# D2522AA register map
Vendor: Dialog; Series: D2522AA; File version: 1.2
CPU: CM0 r1p0, little endian, MPU, FPU, 3 interrupt priority bits
Registers are 32-bit, read-write, reset 0x0 unless marked. A register's access mark holds for its fields unless they carry their own. Offsets are from the block's base; [hi:lo] are bit positions; {n}, {i} and the like mark numbered series; 'fields as' and 'values as' point back to an identical list.

## RFCU_POWER — RFCU_POWER registers
Base 0x40020200
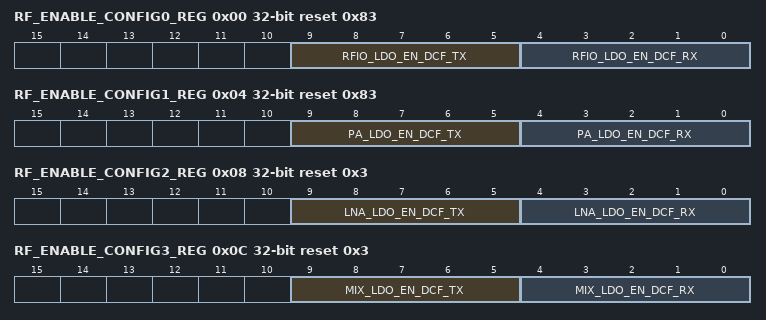
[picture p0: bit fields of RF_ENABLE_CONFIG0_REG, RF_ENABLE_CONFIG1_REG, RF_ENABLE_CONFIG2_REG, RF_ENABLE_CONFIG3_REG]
0x00 RF_ENABLE_CONFIG0_REG reset 0x83
  [9:5] RFIO_LDO_EN_DCF_TX — DCF timer for rfio_ldo_en in tx mode.
  [4:0] RFIO_LDO_EN_DCF_RX — DCF timer for rfio_ldo_en in rx mode
0x04 RF_ENABLE_CONFIG1_REG reset 0x83
  [9:5] PA_LDO_EN_DCF_TX — DCF timer for pa_ldo_en in tx mode
  [4:0] PA_LDO_EN_DCF_RX — DCF timer for pa_ldo_en in rx mode
0x08 RF_ENABLE_CONFIG2_REG reset 0x3
  [9:5] LNA_LDO_EN_DCF_TX — DCF timer for lna_ldo_en in tx mode
  [4:0] LNA_LDO_EN_DCF_RX — DCF timer for lna_ldo_en in rx mode
0x0C RF_ENABLE_CONFIG3_REG reset 0x3
  [9:5] MIX_LDO_EN_DCF_TX — DCF timer for mix_ldo_en in tx mode
  [4:0] MIX_LDO_EN_DCF_RX — DCF timer for mix_ldo_en in rx mode
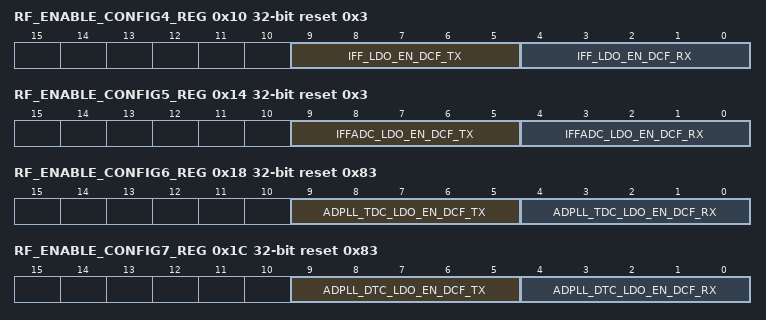
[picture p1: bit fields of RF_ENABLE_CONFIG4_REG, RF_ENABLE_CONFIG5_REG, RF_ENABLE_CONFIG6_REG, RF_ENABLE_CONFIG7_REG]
0x10 RF_ENABLE_CONFIG4_REG reset 0x3
  [9:5] IFF_LDO_EN_DCF_TX — DCF timer for iff_ldo_en in tx mode
  [4:0] IFF_LDO_EN_DCF_RX — DCF timer for iff_ldo_en in rx mode
0x14 RF_ENABLE_CONFIG5_REG reset 0x3
  [9:5] IFFADC_LDO_EN_DCF_TX — DCF timer for iffadc_ldo_en in tx mode
  [4:0] IFFADC_LDO_EN_DCF_RX — DCF timer for iffadc_ldo_en in rx mode
0x18 RF_ENABLE_CONFIG6_REG reset 0x83
  [9:5] ADPLL_TDC_LDO_EN_DCF_TX — DCF timer for adpll_tdc_ldo_en in tx mode
  [4:0] ADPLL_TDC_LDO_EN_DCF_RX — DCF timer for adpll_tdc_ldo_en in rx mode
0x1C RF_ENABLE_CONFIG7_REG reset 0x83
  [9:5] ADPLL_DTC_LDO_EN_DCF_TX — DCF timer for adpll_dtc_ldo_en in tx mode
  [4:0] ADPLL_DTC_LDO_EN_DCF_RX — DCF timer for adpll_dtc_ldo_en in rx mode
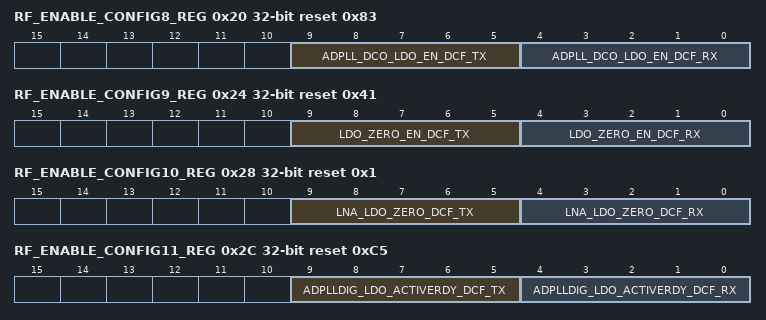
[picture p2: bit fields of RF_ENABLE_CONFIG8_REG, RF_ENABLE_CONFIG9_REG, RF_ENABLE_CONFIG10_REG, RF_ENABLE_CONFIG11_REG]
0x20 RF_ENABLE_CONFIG8_REG reset 0x83
  [9:5] ADPLL_DCO_LDO_EN_DCF_TX — DCF timer for adpll_dco_ldo_en in tx mode
  [4:0] ADPLL_DCO_LDO_EN_DCF_RX — DCF timer for adpll_dco_ldo_en in rx mode
0x24 RF_ENABLE_CONFIG9_REG reset 0x41
  [9:5] LDO_ZERO_EN_DCF_TX — DCF timer for ldo_zero_en in tx mode
  [4:0] LDO_ZERO_EN_DCF_RX — DCF timer for ldo_zero_en in rx mode
0x28 RF_ENABLE_CONFIG10_REG reset 0x1
  [9:5] LNA_LDO_ZERO_DCF_TX — DCF timer for lna_ldo_zero in tx mode
  [4:0] LNA_LDO_ZERO_DCF_RX — DCF timer for lna_ldo_zero in rx mode
0x2C RF_ENABLE_CONFIG11_REG reset 0xC5
  [9:5] ADPLLDIG_LDO_ACTIVERDY_DCF_TX — DCF timer for adplldig_ldo_activerdy in tx mode
  [4:0] ADPLLDIG_LDO_ACTIVERDY_DCF_RX — DCF timer for adplldig_ldo_activerdy in rx mode
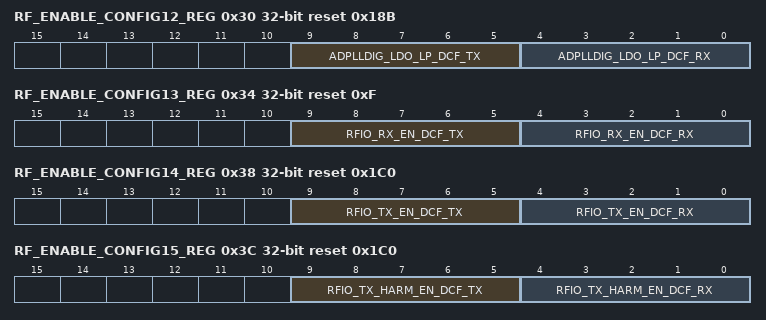
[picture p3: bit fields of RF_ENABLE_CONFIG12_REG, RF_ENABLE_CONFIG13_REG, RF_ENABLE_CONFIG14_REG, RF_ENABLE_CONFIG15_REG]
0x30 RF_ENABLE_CONFIG12_REG reset 0x18B
  [9:5] ADPLLDIG_LDO_LP_DCF_TX — DCF timer for adplldig_ldo_lp in tx mode
  [4:0] ADPLLDIG_LDO_LP_DCF_RX — DCF timer for adplldig_ldo_lp in rx mode
0x34 RF_ENABLE_CONFIG13_REG reset 0xF
  [9:5] RFIO_RX_EN_DCF_TX — DCF timer for rfio_rx_en in tx mode
  [4:0] RFIO_RX_EN_DCF_RX — DCF timer for rfio_rx_en in rx mode
0x38 RF_ENABLE_CONFIG14_REG reset 0x1C0
  [9:5] RFIO_TX_EN_DCF_TX — DCF timer for rfio_tx_en in tx mode
  [4:0] RFIO_TX_EN_DCF_RX — DCF timer for rfio_tx_en in rx mode
0x3C RF_ENABLE_CONFIG15_REG reset 0x1C0
  [9:5] RFIO_TX_HARM_EN_DCF_TX — DCF timer for rfio_tx_harm_en in tx mode
  [4:0] RFIO_TX_HARM_EN_DCF_RX — DCF timer for rfio_tx_harm_en in rx mode
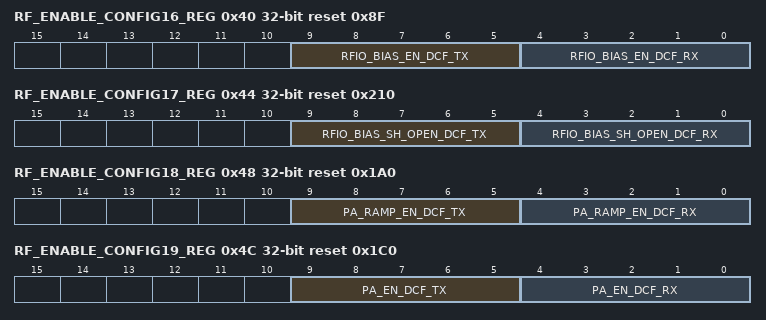
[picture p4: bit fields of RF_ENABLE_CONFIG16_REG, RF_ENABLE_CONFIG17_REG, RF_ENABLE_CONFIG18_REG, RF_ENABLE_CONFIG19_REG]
0x40 RF_ENABLE_CONFIG16_REG reset 0x8F
  [9:5] RFIO_BIAS_EN_DCF_TX — DCF timer for rfio_bias_en in tx mode
  [4:0] RFIO_BIAS_EN_DCF_RX — DCF timer for rfio_bias_en in rx mode
0x44 RF_ENABLE_CONFIG17_REG reset 0x210
  [9:5] RFIO_BIAS_SH_OPEN_DCF_TX — DCF timer for rfio_bias_sh_open in tx mode
  [4:0] RFIO_BIAS_SH_OPEN_DCF_RX — DCF timer for rfio_bias_sh_open in rx mode
0x48 RF_ENABLE_CONFIG18_REG reset 0x1A0
  [9:5] PA_RAMP_EN_DCF_TX — DCF timer for pa_ramp_en in tx mode
  [4:0] PA_RAMP_EN_DCF_RX — DCF timer for pa_ramp_en in rx mode
0x4C RF_ENABLE_CONFIG19_REG reset 0x1C0
  [9:5] PA_EN_DCF_TX — DCF timer for pa_en in tx mode
  [4:0] PA_EN_DCF_RX — DCF timer for pa_en in rx mode
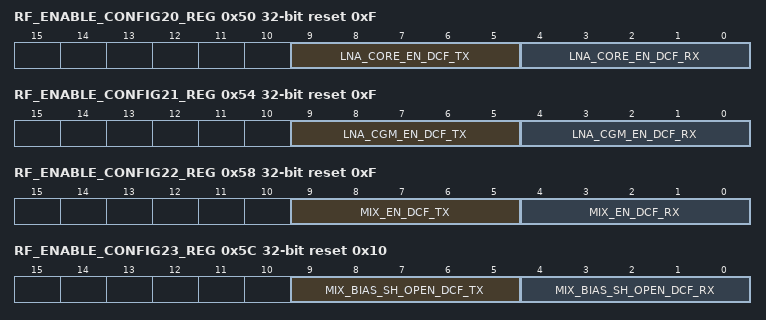
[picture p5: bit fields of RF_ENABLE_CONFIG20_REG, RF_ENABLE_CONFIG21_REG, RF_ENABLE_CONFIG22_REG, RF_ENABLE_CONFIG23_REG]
0x50 RF_ENABLE_CONFIG20_REG reset 0xF
  [9:5] LNA_CORE_EN_DCF_TX — DCF timer for lna_core_en in tx mode
  [4:0] LNA_CORE_EN_DCF_RX — DCF timer for lna_core_en in rx mode
0x54 RF_ENABLE_CONFIG21_REG reset 0xF
  [9:5] LNA_CGM_EN_DCF_TX — DCF timer for lna_cgm_en in tx mode
  [4:0] LNA_CGM_EN_DCF_RX — DCF timer for lna_cgm_en in rx mode
0x58 RF_ENABLE_CONFIG22_REG reset 0xF
  [9:5] MIX_EN_DCF_TX — DCF timer for mix_en in tx mode
  [4:0] MIX_EN_DCF_RX — DCF timer for mix_en in rx mode
0x5C RF_ENABLE_CONFIG23_REG reset 0x10
  [9:5] MIX_BIAS_SH_OPEN_DCF_TX — DCF timer for mix_bias_sh_open in tx mode
  [4:0] MIX_BIAS_SH_OPEN_DCF_RX — DCF timer for mix_bias_sh_open in rx mode
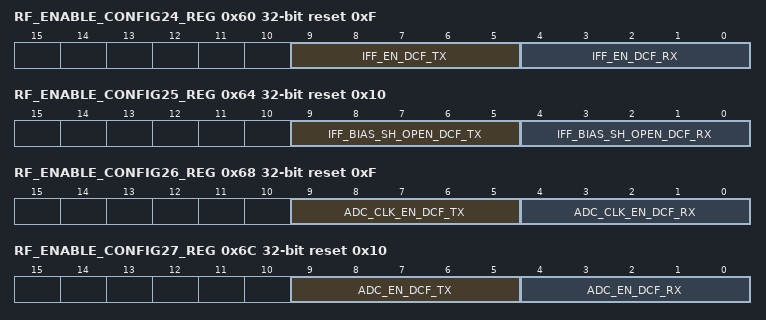
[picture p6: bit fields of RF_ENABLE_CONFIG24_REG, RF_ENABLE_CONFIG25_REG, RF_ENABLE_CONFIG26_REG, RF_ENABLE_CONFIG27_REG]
0x60 RF_ENABLE_CONFIG24_REG reset 0xF
  [9:5] IFF_EN_DCF_TX — DCF timer for iff_en in tx mode
  [4:0] IFF_EN_DCF_RX — DCF timer for iff_en in rx mode
0x64 RF_ENABLE_CONFIG25_REG reset 0x10
  [9:5] IFF_BIAS_SH_OPEN_DCF_TX — DCF timer for iff_bias_sh_open in tx mode
  [4:0] IFF_BIAS_SH_OPEN_DCF_RX — DCF timer for iff_bias_sh_open in rx mode
0x68 RF_ENABLE_CONFIG26_REG reset 0xF
  [9:5] ADC_CLK_EN_DCF_TX — DCF timer for adc_clk_en in tx mode
  [4:0] ADC_CLK_EN_DCF_RX — DCF timer for adc_clk_en in rx mode
0x6C RF_ENABLE_CONFIG27_REG reset 0x10
  [9:5] ADC_EN_DCF_TX — DCF timer for adc_en in tx mode
  [4:0] ADC_EN_DCF_RX — DCF timer for adc_en in rx mode
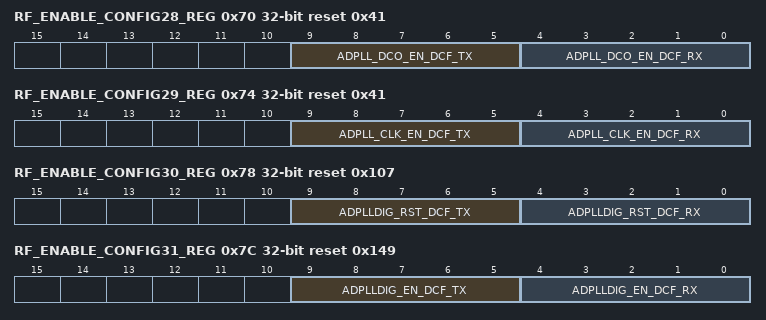
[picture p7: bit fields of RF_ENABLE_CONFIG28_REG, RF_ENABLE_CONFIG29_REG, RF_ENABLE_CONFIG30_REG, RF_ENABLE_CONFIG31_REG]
0x70 RF_ENABLE_CONFIG28_REG reset 0x41
  [9:5] ADPLL_DCO_EN_DCF_TX — DCF timer for adpll_dco_en in tx mode
  [4:0] ADPLL_DCO_EN_DCF_RX — DCF timer for adpll_dco_en in rx mode
0x74 RF_ENABLE_CONFIG29_REG reset 0x41
  [9:5] ADPLL_CLK_EN_DCF_TX — DCF timer for adpll_clk_en in tx mode
  [4:0] ADPLL_CLK_EN_DCF_RX — DCF timer for adpll_clk_en in rx mode
0x78 RF_ENABLE_CONFIG30_REG reset 0x107
  [9:5] ADPLLDIG_RST_DCF_TX — DCF timer for adplldig_rst in tx mode
  [4:0] ADPLLDIG_RST_DCF_RX — DCF timer for adplldig_rst in rx mode
0x7C RF_ENABLE_CONFIG31_REG reset 0x149
  [9:5] ADPLLDIG_EN_DCF_TX — DCF timer for adplldig_en in tx mode
  [4:0] ADPLLDIG_EN_DCF_RX — DCF timer for adplldig_en in rx mode
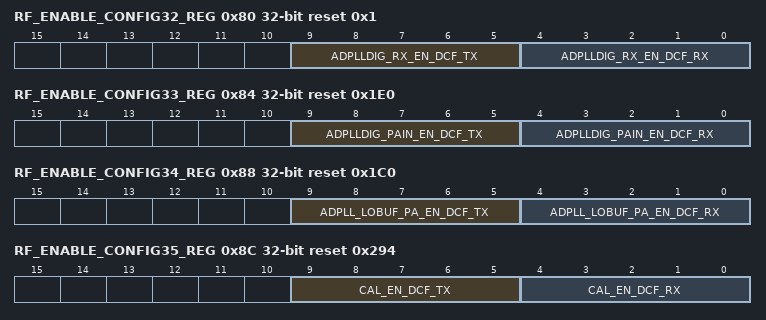
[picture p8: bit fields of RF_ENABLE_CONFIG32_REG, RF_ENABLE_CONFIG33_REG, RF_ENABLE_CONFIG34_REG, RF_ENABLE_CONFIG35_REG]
0x80 RF_ENABLE_CONFIG32_REG reset 0x1
  [9:5] ADPLLDIG_RX_EN_DCF_TX — DCF timer for adplldig_rx_en in tx mode
  [4:0] ADPLLDIG_RX_EN_DCF_RX — DCF timer for adplldig_rx_en in rx mode
0x84 RF_ENABLE_CONFIG33_REG reset 0x1E0
  [9:5] ADPLLDIG_PAIN_EN_DCF_TX — DCF timer for adplldig_pain_en in tx mode
  [4:0] ADPLLDIG_PAIN_EN_DCF_RX — DCF timer for adplldig_pain_en in rx mode
0x88 RF_ENABLE_CONFIG34_REG reset 0x1C0
  [9:5] ADPLL_LOBUF_PA_EN_DCF_TX — DCF timer for adpll_lobuf_pa_en in tx mode
  [4:0] ADPLL_LOBUF_PA_EN_DCF_RX — DCF timer for adpll_lobuf_pa_en in rx mode
0x8C RF_ENABLE_CONFIG35_REG reset 0x294
  [9:5] CAL_EN_DCF_TX — DCF timer for cal_en in tx mode
  [4:0] CAL_EN_DCF_RX — DCF timer for cal_en in rx mode
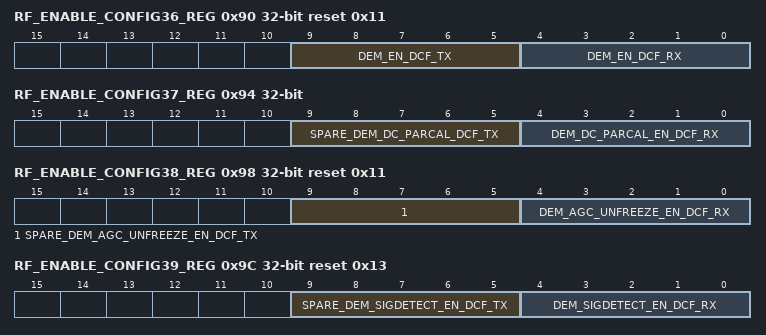
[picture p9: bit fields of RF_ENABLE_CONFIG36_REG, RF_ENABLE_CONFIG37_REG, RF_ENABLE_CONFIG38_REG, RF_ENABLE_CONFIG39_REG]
0x90 RF_ENABLE_CONFIG36_REG reset 0x11
  [9:5] DEM_EN_DCF_TX — DCF timer for dem_en in tx mode
  [4:0] DEM_EN_DCF_RX — DCF timer for dem_en in rx mode
0x94 RF_ENABLE_CONFIG37_REG
  [9:5] SPARE_DEM_DC_PARCAL_DCF_TX — Spare DCF timer in tx mode
  [4:0] DEM_DC_PARCAL_EN_DCF_RX — DCF timer for DC partial Calibration enable in rx mode. It is OR'd with the relevant register bit that enables the partial calibration.
0x98 RF_ENABLE_CONFIG38_REG reset 0x11
  [9:5] SPARE_DEM_AGC_UNFREEZE_EN_DCF_TX — Spare DCF timer in tx mode
  [4:0] DEM_AGC_UNFREEZE_EN_DCF_RX — DCF timer for unfreezing the AGC in rx mode
0x9C RF_ENABLE_CONFIG39_REG reset 0x13
  [9:5] SPARE_DEM_SIGDETECT_EN_DCF_TX — Spare DCF timer in tx mode
  [4:0] DEM_SIGDETECT_EN_DCF_RX — DCF timer for enabling the signal_detect in rx mode
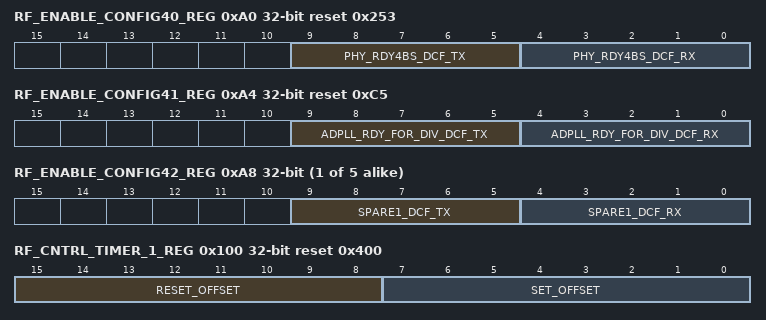
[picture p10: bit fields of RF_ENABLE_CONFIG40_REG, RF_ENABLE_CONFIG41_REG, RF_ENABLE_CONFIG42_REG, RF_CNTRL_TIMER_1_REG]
0xA0 RF_ENABLE_CONFIG40_REG reset 0x253
  [9:5] PHY_RDY4BS_DCF_TX — DCF timer for PHY_RDY4BS in tx mode.
  [4:0] PHY_RDY4BS_DCF_RX — DCF timer for PHY_RDY4BS in rx mode.
0xA4 RF_ENABLE_CONFIG41_REG reset 0xC5
  [9:5] ADPLL_RDY_FOR_DIV_DCF_TX — "Ready for the Dividers" DCF timer in tx mode.
  [4:0] ADPLL_RDY_FOR_DIV_DCF_RX — "Ready for the Dividers" DCF timer in tx mode.
{0x0+4i} RF_ENABLE_CONFIG{i}_REG (i=42..46)
  [9:5] SPARE{i-41}_DCF_TX — Spare DCF timer in tx mode.
  [4:0] SPARE{i-41}_DCF_RX — Spare DCF timer in rx mode.
0x100 RF_CNTRL_TIMER_1_REG reset 0x400
  [15:8] RESET_OFFSET — Offset w.r.t. end switch instant eo_rx/eo_tx
  [7:0] SET_OFFSET — Offset w.r.t. start switch instant so_rx/so_tx.
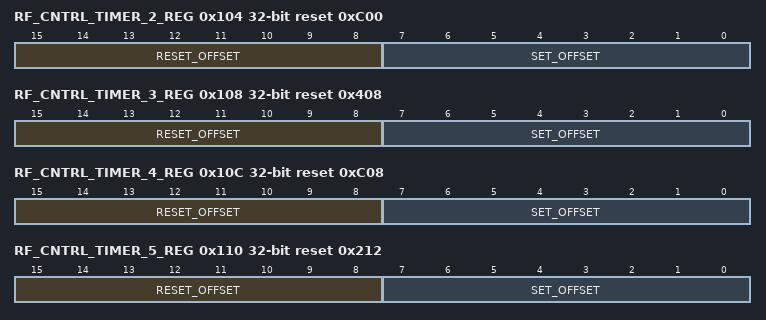
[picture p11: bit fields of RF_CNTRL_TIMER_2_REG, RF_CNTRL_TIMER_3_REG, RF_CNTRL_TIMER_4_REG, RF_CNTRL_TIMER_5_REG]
0x104 RF_CNTRL_TIMER_2_REG reset 0xC00
  [15:8] RESET_OFFSET — Offset w.r.t. end switch instant eo_rx/eo_tx.
  [7:0] SET_OFFSET — Offset w.r.t. start switch instant so_rx/so_tx.
0x108 RF_CNTRL_TIMER_3_REG reset 0x408
  fields as RF_CNTRL_TIMER_2_REG
0x10C RF_CNTRL_TIMER_4_REG reset 0xC08
  [15:8] RESET_OFFSET — Offset w.r.t. end switch instant eo_rx/eo_tx.
  [7:0] SET_OFFSET — Offset w.r.t. start switch instant so_rx/eo_tx.
0x110 RF_CNTRL_TIMER_5_REG reset 0x212
  fields as RF_CNTRL_TIMER_4_REG
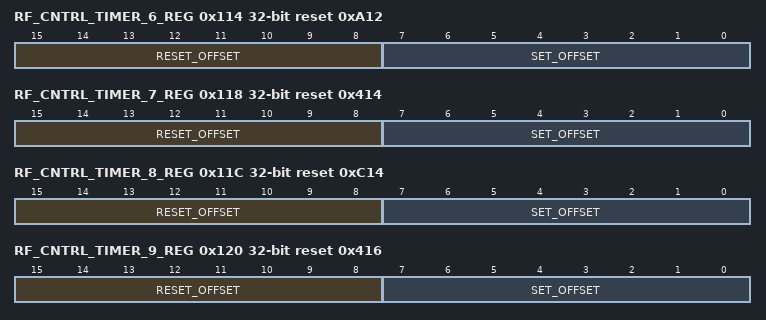
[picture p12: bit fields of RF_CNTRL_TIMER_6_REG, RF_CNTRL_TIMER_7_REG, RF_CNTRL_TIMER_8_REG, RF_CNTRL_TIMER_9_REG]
0x114 RF_CNTRL_TIMER_6_REG reset 0xA12
  fields as RF_CNTRL_TIMER_4_REG
0x118 RF_CNTRL_TIMER_7_REG reset 0x414
  [15:8] RESET_OFFSET — Offset w.r.t. end switch instant eo_tx/eo_tx.
  [7:0] SET_OFFSET — Offset w.r.t. start switch instant so_tx/eo_tx.
0x11C RF_CNTRL_TIMER_8_REG reset 0xC14
  fields as RF_CNTRL_TIMER_4_REG
0x120 RF_CNTRL_TIMER_9_REG reset 0x416
  fields as RF_CNTRL_TIMER_4_REG
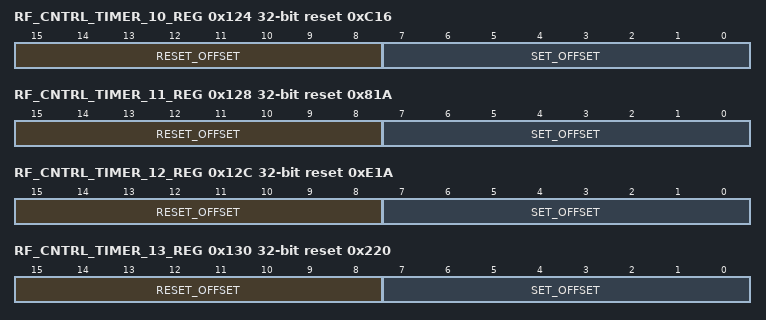
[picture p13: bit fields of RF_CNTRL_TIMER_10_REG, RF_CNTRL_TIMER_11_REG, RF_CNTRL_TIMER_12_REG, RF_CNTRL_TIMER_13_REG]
0x124 RF_CNTRL_TIMER_10_REG reset 0xC16
  fields as RF_CNTRL_TIMER_4_REG
0x128 RF_CNTRL_TIMER_11_REG reset 0x81A
  fields as RF_CNTRL_TIMER_7_REG
0x12C RF_CNTRL_TIMER_12_REG reset 0xE1A
  fields as RF_CNTRL_TIMER_4_REG
0x130 RF_CNTRL_TIMER_13_REG reset 0x220
  fields as RF_CNTRL_TIMER_4_REG
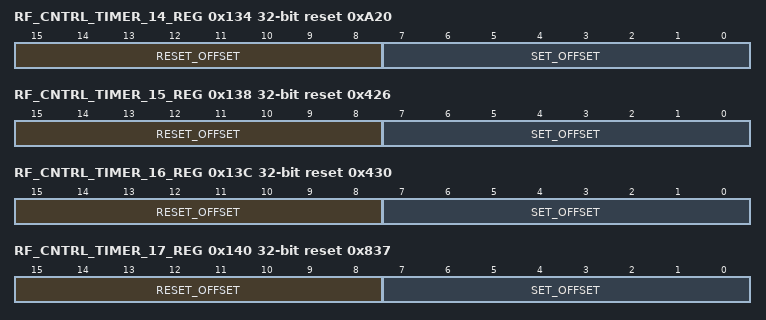
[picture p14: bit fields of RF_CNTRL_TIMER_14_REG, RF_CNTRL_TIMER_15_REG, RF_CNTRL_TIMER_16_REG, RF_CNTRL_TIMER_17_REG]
0x134 RF_CNTRL_TIMER_14_REG reset 0xA20
  fields as RF_CNTRL_TIMER_4_REG
0x138 RF_CNTRL_TIMER_15_REG reset 0x426
  fields as RF_CNTRL_TIMER_4_REG
0x13C RF_CNTRL_TIMER_16_REG reset 0x430
  fields as RF_CNTRL_TIMER_4_REG
0x140 RF_CNTRL_TIMER_17_REG reset 0x837
  fields as RF_CNTRL_TIMER_4_REG
0x144 RF_CNTRL_TIMER_18_REG reset 0x846
  fields as RF_CNTRL_TIMER_4_REG
0x148 RF_CNTRL_TIMER_19_REG reset 0x850
  fields as RF_CNTRL_TIMER_4_REG
0x14C RF_CNTRL_TIMER_20_REG reset 0x125A
  fields as RF_CNTRL_TIMER_4_REG
{0xFC+4i} RF_CNTRL_TIMER_{i}_REG (i=21..31)
  fields as RF_CNTRL_TIMER_4_REG
0x180 RF_ALWAYS_EN1_REG (reset mask 0x7FFFFFFF)
  [31] ALW_EN_ADPLLDIG_EN, [30] ALW_EN_ADPLLDIG_RST, [29] ALW_EN_ADPLL_CLK_EN, [28] ALW_EN_ADPLL_DCO_EN, [27] ALW_EN_ADC_EN, [26] ALW_EN_ADC_CLK_EN, [25] ALW_EN_IFF_BIAS_SH_OPEN, [24] ALW_EN_IFF_EN, [23] ALW_EN_MIX_BIAS_SH_OPEN, [22] ALW_EN_MIX_EN, [21] ALW_EN_LNA_CGM_EN, [20] ALW_EN_LNA_CORE_EN, [19] ALW_EN_PA_EN, [18] ALW_EN_PA_RAMP_EN, [17] ALW_EN_RFIO_BIAS_SH_OPEN, [16] ALW_EN_RFIO_BIAS_EN, [15] ALW_EN_RFIO_TX_HARM_EN, [14] ALW_EN_RFIO_TX_EN, [13] ALW_EN_RFIO_RX_EN, [12] ALW_EN_ADPLLDIG_LDO_LP, [11] ALW_EN_ADPLLDIG_LDO_ACTIVERDY, [10] ALW_EN_LNA_LDO_ZERO, [9] ALW_EN_LDO_ZERO_EN, [8] ALW_EN_ADPLL_DCO_LDO_EN, [7] ALW_EN_ADPLL_DTC_LDO_EN, [6] ALW_EN_ADPLL_TDC_LDO_EN, [5] ALW_EN_IFFADC_LDO_EN, [4] ALW_EN_IFF_LDO_EN, [3] ALW_EN_MIX_LDO_EN, [2] ALW_EN_LNA_LDO_EN, [1] ALW_EN_PA_LDO_EN, [0] ALW_EN_RFIO_LDO_EN
0x184 RF_ALWAYS_EN2_REG
  [n+9] ALW_EN_SPARE{n} (n=1..5), [9] ALW_EN_ADPLL_RDY_FOR_DIV, [8] ALW_EN_PHY_RDY4BS, [7] ALW_EN_DEM_SIGDETECT_EN, [6] ALW_EN_DEM_AGC_UNFREEZE_EN, [5] ALW_EN_DEM_DC_PARCAL_EN, [4] ALW_EN_DEM_EN, [3] ALW_EN_CAL_EN, [2] ALW_EN_ADPLL_LOBUF_PA_EN, [1] ALW_EN_ADPLL_PAIN_EN, [0] ALW_EN_ADPLLDIG_RX_EN
0x188 RF_PORT_EN_REG
  [2n+1] RF_PORT{n}_TX (n=0..4) — Enable port by TX, timing according RF_CNTRL_TIMER_{n+27}_REG
  [2n] RF_PORT{n}_RX (n=0..4) — Enable port by RX, timing according RF_CNTRL_TIMER_{n+27}_REG
0x18C RF_PORT_POL_REG
  [n] RF_PORT{n}_POL (n=0..4) — Inverts polarity of RF_PORT
